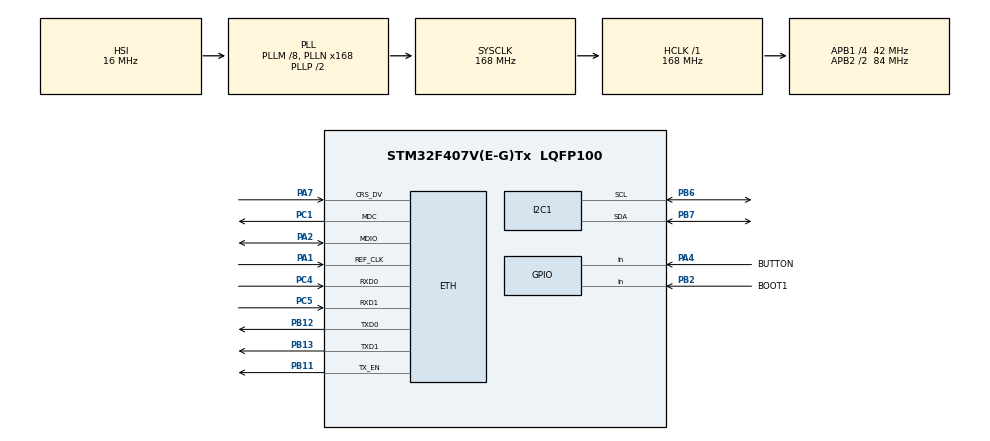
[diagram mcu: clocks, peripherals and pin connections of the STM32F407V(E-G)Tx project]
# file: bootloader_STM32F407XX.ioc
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Mcu.Family=STM32F4
RCC.CortexFreq_Value=168000000
PA7.Mode=RMII
PA14.GPIO_Label=SWCLK
PC4.Signal=ETH_RXD0
ETH.MACAddr=4A\:43\:4F\:52\:39\:33
LWIP.LWIP_DHCP=0
PC5.Mode=RMII
RCC.APB1CLKDivider=RCC_HCLK_DIV4
PB11.Signal=ETH_TX_EN
PB13.Signal=ETH_TXD1
ETH.PhyAddress=0
RCC.SYSCLKSource=RCC_SYSCLKSOURCE_PLLCLK
ProjectManager.StackSize=0x400
VP_LWIP_VS_Enabled.Mode=Enabled
LWIP.GATEWAY_ADDRESS=192.168.001.001
LWIP.NETMASK_ADDRESS=255.255.255.000
PA13.Signal=SYS_JTMS-SWDIO
PB11.Mode=RMII
ProjectManager.TargetToolchain=STM32CubeIDE
RCC.HCLKFreq_Value=168000000
RCC.APB2TimFreq_Value=168000000
PB6.Signal=I2C1_SCL
PB6.Mode=I2C
RCC.LSE_VALUE=32768
PA1.Signal=ETH_REF_CLK
RCC.AHBFreq_Value=168000000
RCC.HSE_VALUE=8000000
PA4.GPIO_PuPd=GPIO_PULLUP
PB2.Signal=GPIO_Input
PB3.Mode=Trace_Asynchronous_SW
board=STM32F407G-DISC1
RCC.VCOOutputFreq_Value=336000000
LWIP.LWIP_TCP=0
LWIP.LWIP_TFTP=1
RCC.APB2Freq_Value=84000000
PA1.Mode=RMII
PB2.GPIO_Mode=GPIO_MODE_INPUT
LWIP.MEM_SIZE=10*1024
PA14.Mode=Trace_Asynchronous_SW
PB7.Signal=I2C1_SDA
PA13.Mode=Trace_Asynchronous_SW
Mcu.Name=STM32F407V(E-G)Tx
PB2.GPIO_PuPd=GPIO_NOPULL
PA2.Signal=ETH_MDIO
PA13.GPIO_Label=SWDIO
RCC.48MHZClocksFreq_Value=48000000
PB3.Signal=SYS_JTDO-SWO
PA4.Signal=GPIO_Input
RCC.SYSCLKFreq_VALUE=168000000
Mcu.Package=LQFP100
ETH.MediaInterface=ETH_MEDIA_INTERFACE_RMII
PB12.Mode=RMII
LWIP.LWIP_NETIF_STATUS_CALLBACK=0
PB7.Mode=I2C
PA14.Signal=SYS_JTCK-SWCLK
PB2.GPIO_Label=BOOT1
ProjectManager.HeapSize=0x200
LWIP.Version=v2.1.2_Cube
RCC.HSI_VALUE=16000000
RCC.PLLQ=7
NVIC.PriorityGroup=NVIC_PRIORITYGROUP_0
RCC.APB2CLKDivider=RCC_HCLK_DIV2
RCC.PLLM=8
RCC.PLLN=168
RCC.APB1TimFreq_Value=84000000
PA2.Mode=RMII
PC5.Signal=ETH_RXD1
PB13.Mode=RMII
RCC.APB1Freq_Value=42000000
VP_CRC_VS_CRC.Mode=CRC_Activate
PA4.GPIO_Label=BUTTON
PC1.Signal=ETH_MDC
PB12.Signal=ETH_TXD0
PC4.Mode=RMII
PC1.Mode=RMII
LWIP.IP_ADDRESS=192.168.001.110
PA7.Signal=ETH_CRS_DV
PB3.GPIO_Label=SWO

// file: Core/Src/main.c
/* USER CODE BEGIN Header */
/**
  ******************************************************************************
  * @file           : main.c
  * @brief          : Main program body
  ******************************************************************************
  * @attention
  *
  * <h2><center>&copy; Copyright (c) 2020 STMicroelectronics.
  * All rights reserved.</center></h2>
  *
  * This software component is licensed by ST under BSD 3-Clause license,
  * the "License"; You may not use this file except in compliance with the
  * License. You may obtain a copy of the License at:
  *                        opensource.org/licenses/BSD-3-Clause
  *
  ******************************************************************************
  */
/* USER CODE END Header */
#include "main.h"
#include "crc.h"
#include "i2c.h"
#include "lwip.h"
#include "gpio.h"

/* USER CODE BEGIN Includes */
#include "bootloader.h"
#include "tftpServer.h"
#include "udpServer.h"
/* USER CODE END Includes */

void SystemClock_Config(void);

int main(void)
{

  /* MCU Configuration--------------------------------------------------------*/

  /* Reset of all peripherals, Initializes the Flash interface and the Systick. */
  HAL_Init();

  /* Configure the system clock */
  SystemClock_Config();

  /* Initialize all configured peripherals */
  MX_GPIO_Init();
  MX_CRC_Init();
  MX_LWIP_Init();
  MX_I2C1_Init();
  /* USER CODE BEGIN 2 */
  uint8_t bootloaderInitRam    = 0;
  uint8_t bootloaderInitButton = 0;

  bootloaderInitRam = * (volatile uint8_t *) BOOTLOADER_INIT_ADDRESS;
  bootloaderInitButton = HAL_GPIO_ReadPin(BOOTLOADER_RESET_PORT, BOOTLOADER_RESET_PIN);

  /* USER CODE END 2 */

  /* Infinite loop */
  /* USER CODE BEGIN WHILE */
  if (bootloaderInitRam == BOOTLOADER_INIT_VALUE || bootloaderInitButton == RESET){
	  BOOTLOADER_START = BOOTLOADER_RESET_VALUE;
  	  udpServer_init();
  	  tftp_init(&tftpContext);
  	  bootloaderReadData();
  }
  else{
  	  bootloaderJumpToUserApp();
  }
    /* USER CODE END WHILE */

}

void SystemClock_Config(void)
{
  RCC_OscInitTypeDef RCC_OscInitStruct = {0};
  RCC_ClkInitTypeDef RCC_ClkInitStruct = {0};

  /** Configure the main internal regulator output voltage
  */
  __HAL_RCC_PWR_CLK_ENABLE();
  __HAL_PWR_VOLTAGESCALING_CONFIG(PWR_REGULATOR_VOLTAGE_SCALE1);
  /** Initializes the RCC Oscillators according to the specified parameters
  * in the RCC_OscInitTypeDef structure.
  */
  RCC_OscInitStruct.OscillatorType = RCC_OSCILLATORTYPE_HSI;
  RCC_OscInitStruct.HSIState = RCC_HSI_ON;
  RCC_OscInitStruct.HSICalibrationValue = RCC_HSICALIBRATION_DEFAULT;
  RCC_OscInitStruct.PLL.PLLState = RCC_PLL_ON;
  RCC_OscInitStruct.PLL.PLLSource = RCC_PLLSOURCE_HSI;
  RCC_OscInitStruct.PLL.PLLM = 8;
  RCC_OscInitStruct.PLL.PLLN = 168;
  RCC_OscInitStruct.PLL.PLLP = RCC_PLLP_DIV2;
  RCC_OscInitStruct.PLL.PLLQ = 7;
  if (HAL_RCC_OscConfig(&RCC_OscInitStruct) != HAL_OK)
  {
    Error_Handler();
  }
  /** Initializes the CPU, AHB and APB buses clocks
  */
  RCC_ClkInitStruct.ClockType = RCC_CLOCKTYPE_HCLK|RCC_CLOCKTYPE_SYSCLK
                              |RCC_CLOCKTYPE_PCLK1|RCC_CLOCKTYPE_PCLK2;
  RCC_ClkInitStruct.SYSCLKSource = RCC_SYSCLKSOURCE_PLLCLK;
  RCC_ClkInitStruct.AHBCLKDivider = RCC_SYSCLK_DIV1;
  RCC_ClkInitStruct.APB1CLKDivider = RCC_HCLK_DIV4;
  RCC_ClkInitStruct.APB2CLKDivider = RCC_HCLK_DIV2;

  if (HAL_RCC_ClockConfig(&RCC_ClkInitStruct, FLASH_LATENCY_5) != HAL_OK)
  {
    Error_Handler();
  }
}

void Error_Handler(void)
{
}

/************************ (C) COPYRIGHT STMicroelectronics *****END OF FILE****/
